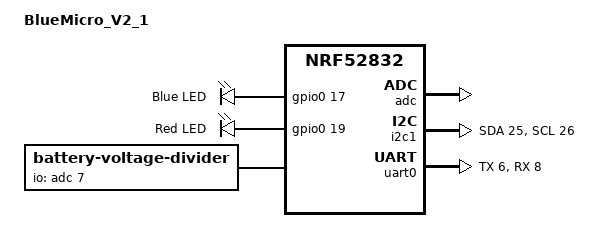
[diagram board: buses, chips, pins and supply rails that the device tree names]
/*
 * Copyright (c) 2020 Pete Johanson, Derek Schmell
 *
 * SPDX-License-Identifier: MIT
 */

/dts-v1/;
#include <nordic/nrf52832_qfaa.dtsi>
#include "arduino_pro_micro_pins.dtsi"

/ {
	model = "BlueMicro_V2_1";
	compatible = "bluemicro,v2_1";

	chosen {
		zephyr,code-partition = &code_partition;
		zephyr,sram = &sram0;
		zephyr,flash = &flash0;
	};

	leds {
		compatible = "gpio-leds";
		blue_led: led_0 {
			gpios = <&gpio0 17 GPIO_ACTIVE_HIGH>;
			label = "Blue LED";
		};
		red_led: led_1 {
			gpios = <&gpio0 19 GPIO_ACTIVE_HIGH>;
			label = "Red LED";
		};
	};

	vbatt {
		compatible = "zmk,battery-voltage-divider";
		label = "BATTERY";
		io-channels = <&adc 7>;
		output-ohms = <2000000>;
		full-ohms = <(2000000 + 806000)>;
	};

};

&adc {
	status = "okay";
};

&gpiote {
	status = "okay";
};

&gpio0 {
	status = "okay";
};

&i2c1 {
	compatible = "nordic,nrf-twi";
	sda-pin = <25>;
	scl-pin = <26>;
};

&uart0 {
	compatible = "nordic,nrf-uarte";
	tx-pin = <6>;
	rx-pin = <8>;
};

&flash0 {
	/*
	 * For more information, see:
	 * http://docs.zephyrproject.org/latest/devices/dts/flash_partitions.html
	 */
	partitions {
		compatible = "fixed-partitions";
		#address-cells = <1>;
		#size-cells = <1>;

		sd_partition: partition@0 {
			label = "softdevice";
			reg = <0x00000000 0x00026000>;
		};
		code_partition: partition@26000 {
			label = "code_partition";
			reg = <0x00026000 0x00047000>;
		};

		/*
		 * The flash starting at 0x000ec000 and ending at
		 * 0x000f3fff is reserved for use by the application.
		 */

		/*
		 * Storage partition will be used by FCB/LittleFS/NVS
		 * if enabled.
		 */
		storage_partition: partition@47000 {
			label = "storage";
			reg = <0x00047000 0x00008000>;
		};

		boot_partition: partition@74000 {
			label = "adafruit_boot";
			reg = <0x00074000 0x0000c000>;
		};
	};
};
